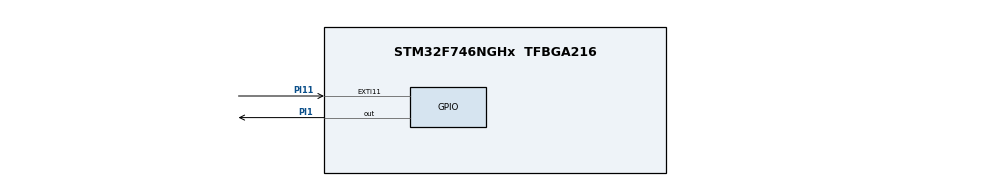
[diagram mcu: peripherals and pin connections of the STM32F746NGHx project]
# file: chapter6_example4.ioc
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CORTEX_M7.default_mode_Activation=1
Mcu.Family=STM32F7
Mcu.Name=STM32F746NGHx
Mcu.Package=TFBGA216
NVIC.EXTI15_10_IRQn=true\:0\:0\:false\:false\:true\:true\:true\:true
NVIC.PriorityGroup=NVIC_PRIORITYGROUP_4
PI1.Signal=GPIO_Output
PI11.Signal=GPXTI11
ProjectManager.HeapSize=0x200
ProjectManager.StackSize=0x400
ProjectManager.TargetToolchain=STM32CubeIDE
RCC.HSE_VALUE=25000000
RCC.HSI_VALUE=16000000
RCC.LSE_VALUE=32768
RCC.USBFreq_Value=96000000
RCC.VCOOutputFreq_Value=192000000
board=custom

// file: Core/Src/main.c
/* USER CODE BEGIN Header */
/**
  ******************************************************************************
  * @file           : main.c
  * @brief          : Main program body
  ******************************************************************************
  * @attention
  *
  * Copyright (c) 2026 STMicroelectronics.
  * All rights reserved.
  *
  * This software is licensed under terms that can be found in the LICENSE file
  * in the root directory of this software component.
  * If no LICENSE file comes with this software, it is provided AS-IS.
  *
  ******************************************************************************
  */
/* USER CODE END Header */
#include "main.h"

void SystemClock_Config(void);
static void MPU_Config(void);
static void MX_GPIO_Init(void);

/* USER CODE BEGIN 0 */

void EXTI_PI11_Init_CMSIS(void);

void EXTI_PI11_Init_CMSIS(void)
{
    /* 1) Enable clock GPIOI + SYSCFG */
    RCC->AHB1ENR |= RCC_AHB1ENR_GPIOIEN;
    RCC->APB2ENR |= RCC_APB2ENR_SYSCFGEN;

    (void)RCC->AHB1ENR;
    (void)RCC->APB2ENR;

    /* 2) GPIOI Pin 11: Input + Pull-up */
    /* MODER11 = 00 (input) */
    GPIOI->MODER &= ~(0x3U << (11U * 2U));

    /* PUPDR11 = 01 (pull-up) */
    GPIOI->PUPDR &= ~(0x3U << (11U * 2U));
    GPIOI->PUPDR |=  (0x1U << (11U * 2U));

    /* 3) Map EXTI11 -> Port I trong SYSCFG_EXTICR3 (EXTI8..11) */
    /* EXTI11 nằm ở EXTICR3, field [15:12] */
    SYSCFG->EXTICR[2] &= ~(0xFU << 12U);
    SYSCFG->EXTICR[2] |=  (0x8U << 12U);  // Port I = 0b1000

    /* 4) Cấu hình EXTI line 11: unmask + falling edge */
    EXTI->IMR  |=  (1U << 11U);   // interrupt request from line 11 not masked
    EXTI->EMR  &= ~(1U << 11U);   // event mask off (không bắt buộc)

    EXTI->RTSR &= ~(1U << 11U);   // tắt rising
    EXTI->FTSR |=  (1U << 11U);   // bật falling

    /* 5) Clear pending (nếu có) */
    EXTI->PR = (1U << 11U);       // write 1 để clear

    /* 6) NVIC: EXTI15_10_IRQn dùng chung cho line 10..15 */
    NVIC_SetPriority(EXTI15_10_IRQn, 5U);
    NVIC_EnableIRQ(EXTI15_10_IRQn);
}

/* USER CODE END 0 */

int main(void)
{

  /* MPU Configuration--------------------------------------------------------*/
  MPU_Config();

  /* MCU Configuration--------------------------------------------------------*/

  /* Reset of all peripherals, Initializes the Flash interface and the Systick. */
  LL_APB1_GRP1_EnableClock(LL_APB1_GRP1_PERIPH_PWR);
  LL_APB2_GRP1_EnableClock(LL_APB2_GRP1_PERIPH_SYSCFG);

  /* System interrupt init*/
  NVIC_SetPriorityGrouping(NVIC_PRIORITYGROUP_4);

  /* SysTick_IRQn interrupt configuration */
  NVIC_SetPriority(SysTick_IRQn, NVIC_EncodePriority(NVIC_GetPriorityGrouping(),15, 0));

  /* Configure the system clock */
  SystemClock_Config();

  /* Initialize all configured peripherals */
  MX_GPIO_Init();

  /* Infinite loop */
  /* USER CODE BEGIN WHILE */
  EXTI_PI11_Init_CMSIS();
  while (1)
  {
    /* USER CODE END WHILE */

  }
}

void SystemClock_Config(void)
{
  LL_FLASH_SetLatency(LL_FLASH_LATENCY_0);
  while(LL_FLASH_GetLatency()!= LL_FLASH_LATENCY_0)
  {
  }
  LL_PWR_SetRegulVoltageScaling(LL_PWR_REGU_VOLTAGE_SCALE3);
  LL_PWR_DisableOverDriveMode();
  LL_RCC_HSI_SetCalibTrimming(16);
  LL_RCC_HSI_Enable();

   /* Wait till HSI is ready */
  while(LL_RCC_HSI_IsReady() != 1)
  {

  }
  LL_RCC_SetAHBPrescaler(LL_RCC_SYSCLK_DIV_1);
  LL_RCC_SetAPB1Prescaler(LL_RCC_APB1_DIV_1);
  LL_RCC_SetAPB2Prescaler(LL_RCC_APB2_DIV_1);
  LL_RCC_SetSysClkSource(LL_RCC_SYS_CLKSOURCE_HSI);

   /* Wait till System clock is ready */
  while(LL_RCC_GetSysClkSource() != LL_RCC_SYS_CLKSOURCE_STATUS_HSI)
  {

  }
  LL_Init1msTick(16000000);
  LL_SetSystemCoreClock(16000000);

   /* Set Timers Clock Prescalers */
  LL_RCC_SetTIMPrescaler(LL_RCC_TIM_PRESCALER_TWICE);
}

static void MX_GPIO_Init(void)
{
  LL_EXTI_InitTypeDef EXTI_InitStruct = {0};
  LL_GPIO_InitTypeDef GPIO_InitStruct = {0};

  /* GPIO Ports Clock Enable */
  LL_AHB1_GRP1_EnableClock(LL_AHB1_GRP1_PERIPH_GPIOI);

  /**/
  LL_GPIO_ResetOutputPin(GPIOI, LL_GPIO_PIN_1);

  /**/
  GPIO_InitStruct.Pin = LL_GPIO_PIN_1;
  GPIO_InitStruct.Mode = LL_GPIO_MODE_OUTPUT;
  GPIO_InitStruct.Speed = LL_GPIO_SPEED_FREQ_LOW;
  GPIO_InitStruct.OutputType = LL_GPIO_OUTPUT_PUSHPULL;
  GPIO_InitStruct.Pull = LL_GPIO_PULL_NO;
  LL_GPIO_Init(GPIOI, &GPIO_InitStruct);

  /**/
  LL_SYSCFG_SetEXTISource(LL_SYSCFG_EXTI_PORTI, LL_SYSCFG_EXTI_LINE11);

  /**/
  EXTI_InitStruct.Line_0_31 = LL_EXTI_LINE_11;
  EXTI_InitStruct.LineCommand = ENABLE;
  EXTI_InitStruct.Mode = LL_EXTI_MODE_IT;
  EXTI_InitStruct.Trigger = LL_EXTI_TRIGGER_RISING;
  LL_EXTI_Init(&EXTI_InitStruct);

  /**/
  LL_GPIO_SetPinPull(GPIOI, LL_GPIO_PIN_11, LL_GPIO_PULL_NO);

  /**/
  LL_GPIO_SetPinMode(GPIOI, LL_GPIO_PIN_11, LL_GPIO_MODE_INPUT);

  /* EXTI interrupt init*/
  NVIC_SetPriority(EXTI15_10_IRQn, NVIC_EncodePriority(NVIC_GetPriorityGrouping(),0, 0));
  NVIC_EnableIRQ(EXTI15_10_IRQn);

}

 /* MPU Configuration */

void MPU_Config(void)
{

  /* Disables the MPU */
  LL_MPU_Disable();

  /** Initializes and configures the Region and the memory to be protected
  */
  LL_MPU_ConfigRegion(LL_MPU_REGION_NUMBER0, 0x87, 0x0, LL_MPU_REGION_SIZE_4GB|LL_MPU_TEX_LEVEL0|LL_MPU_REGION_NO_ACCESS|LL_MPU_INSTRUCTION_ACCESS_DISABLE|LL_MPU_ACCESS_SHAREABLE|LL_MPU_ACCESS_NOT_CACHEABLE|LL_MPU_ACCESS_NOT_BUFFERABLE);
  /* Enables the MPU */
  LL_MPU_Enable(LL_MPU_CTRL_PRIVILEGED_DEFAULT);

}

void Error_Handler(void)
{
  __disable_irq();
  while (1)
  {
  }
}
